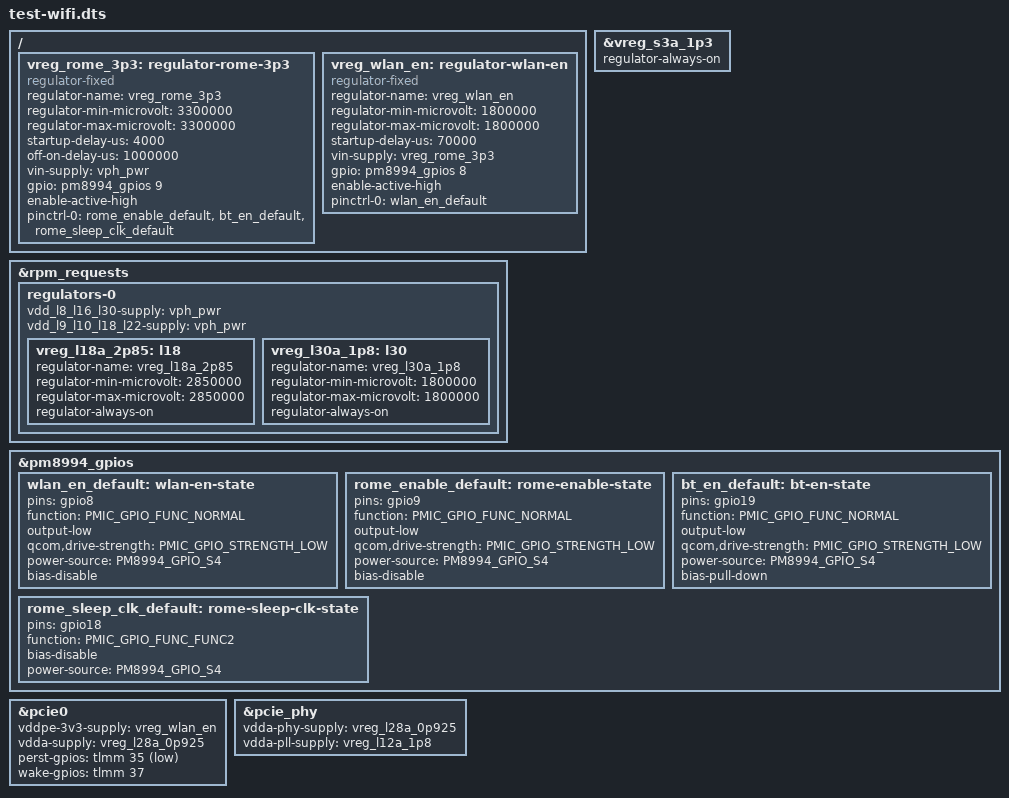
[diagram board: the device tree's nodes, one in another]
// SPDX-License-Identifier: BSD-3-Clause
/*
 * Wi-Fi test: QCA6174 ("Rome") on PCIe0, driven by ath10k_pci.
 * Built on the GPU test DT so the headless GPU setup stays the same.
 *
 * Wiring from the stock DT (qcom,cnss + cnss_wlan_en_vreg / rome_vreg),
 * identical to the Xiaomi MSM8996 boards in msm8996-xiaomi-common.dtsi:
 *  - PM8994 GPIO 9: Rome 3.3 V enable (rome_vreg, 4 ms startup)
 *  - PM8994 GPIO 8: WLAN_EN
 *  - PM8994 GPIO 18 func2: 32.768 kHz sleep clock (divclk4 on db820c)
 *  - TLMM 35 PERST#, TLMM 37 WAKE#
 *  - PM8994 S4 1.8 V I/O, L30 1.8 V crystal, S3 1.3 V core,
 *    L18 antenna switch (stock pm8994_l18_pin_ctrl, 2.7-2.9 V)
 * ath10k doesn't manage the cnss rails, so they're always-on here.
 *
 * BT_EN (PM8994 GPIO 19) must be low while Rome's 3.3 V supply comes up.
 * The bootloader leaves BT_EN high; if the 3.3 V rail rises like that,
 * Rome turns on its PCIe receiver after PERST# but never transmits (the
 * root port sits in Polling.Compliance). Raising BT_EN after a clean
 * power-up is fine. So the 3.3 V regulator is not always-on: it starts
 * off at probe, stays off for off-on-delay-us with BT_EN held low, and is
 * switched on by the PCIe driver through the WLAN_EN regulator chain.
 */

#include <dt-bindings/pinctrl/qcom,pmic-gpio.h>
#include "test-gpu.dts"

/ {
	vreg_rome_3p3: regulator-rome-3p3 {
		compatible = "regulator-fixed";
		regulator-name = "vreg_rome_3p3";
		regulator-min-microvolt = <3300000>;
		regulator-max-microvolt = <3300000>;
		startup-delay-us = <4000>;
		off-on-delay-us = <1000000>;
		vin-supply = <&vph_pwr>;

		gpio = <&pm8994_gpios 9 GPIO_ACTIVE_HIGH>;
		enable-active-high;
		pinctrl-names = "default";
		pinctrl-0 = <&rome_enable_default>, <&bt_en_default>,
			    <&rome_sleep_clk_default>;
	};

	vreg_wlan_en: regulator-wlan-en {
		compatible = "regulator-fixed";
		regulator-name = "vreg_wlan_en";
		regulator-min-microvolt = <1800000>;
		regulator-max-microvolt = <1800000>;
		startup-delay-us = <70000>;
		vin-supply = <&vreg_rome_3p3>;

		gpio = <&pm8994_gpios 8 GPIO_ACTIVE_HIGH>;
		enable-active-high;
		pinctrl-names = "default";
		pinctrl-0 = <&wlan_en_default>;
	};
};

&rpm_requests {
	regulators-0 {
		vdd_l8_l16_l30-supply = <&vph_pwr>;
		vdd_l9_l10_l18_l22-supply = <&vph_pwr>;

		vreg_l18a_2p85: l18 {
			regulator-name = "vreg_l18a_2p85";
			regulator-min-microvolt = <2850000>;
			regulator-max-microvolt = <2850000>;
			regulator-always-on;
		};

		vreg_l30a_1p8: l30 {
			regulator-name = "vreg_l30a_1p8";
			regulator-min-microvolt = <1800000>;
			regulator-max-microvolt = <1800000>;
			regulator-always-on;
		};
	};
};

&vreg_s3a_1p3 {
	regulator-always-on;
};

&pm8994_gpios {
	wlan_en_default: wlan-en-state {
		pins = "gpio8";
		function = PMIC_GPIO_FUNC_NORMAL;
		output-low;
		qcom,drive-strength = <PMIC_GPIO_STRENGTH_LOW>;
		power-source = <PM8994_GPIO_S4>;
		bias-disable;
	};

	rome_enable_default: rome-enable-state {
		pins = "gpio9";
		function = PMIC_GPIO_FUNC_NORMAL;
		output-low;
		qcom,drive-strength = <PMIC_GPIO_STRENGTH_LOW>;
		power-source = <PM8994_GPIO_S4>;
		bias-disable;
	};

	bt_en_default: bt-en-state {
		pins = "gpio19";
		function = PMIC_GPIO_FUNC_NORMAL;
		output-low;
		qcom,drive-strength = <PMIC_GPIO_STRENGTH_LOW>;
		power-source = <PM8994_GPIO_S4>;
		bias-pull-down;
	};

	rome_sleep_clk_default: rome-sleep-clk-state {
		pins = "gpio18";
		function = PMIC_GPIO_FUNC_FUNC2;
		bias-disable;
		power-source = <PM8994_GPIO_S4>;
	};
};

&pcie0 {
	status = "okay";

	/* Rome 3.3 V is always on; the PCIe driver toggles WLAN_EN */
	vddpe-3v3-supply = <&vreg_wlan_en>;
	vdda-supply = <&vreg_l28a_0p925>;

	perst-gpios = <&tlmm 35 GPIO_ACTIVE_LOW>;
	wake-gpios = <&tlmm 37 GPIO_ACTIVE_HIGH>;
};

&pcie_phy {
	status = "okay";

	vdda-phy-supply = <&vreg_l28a_0p925>;
	vdda-pll-supply = <&vreg_l12a_1p8>;
};
